# STM32H7A3xxQ register map
File version: 1.0
Registers are 32-bit, read-write, reset 0x0 unless marked. A register's access mark holds for its fields unless they carry their own. Offsets are from the block's base; [hi:lo] are bit positions; {n}, {i} and the like mark numbered series.

## RAMECC
Base 0x52009000
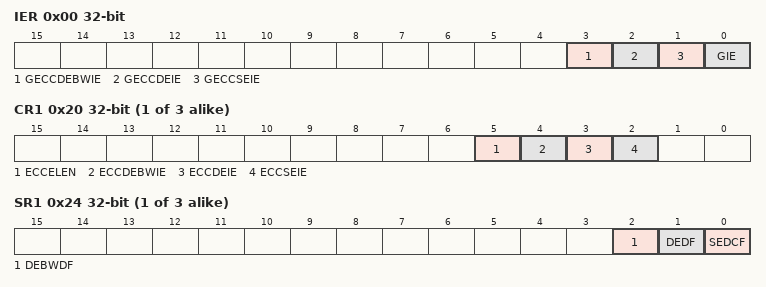
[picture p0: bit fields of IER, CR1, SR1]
0x00 IER — RAMECC interrupt enable register
  [3] GECCDEBWIE — Global ECC double error on byte write (BW) interrupt enable
  [2] GECCDEIE — Global ECC double error interrupt enable
  [1] GECCSEIE — Global ECC single error interrupt enable
  [0] GIE — Global interrupt enable
{0x0+0x20*i} CR{i} (i=1..3) — RAMECC monitor configuration register
  [5] ECCELEN — ECC error latching enable
  [4] ECCDEBWIE — ECC double error on byte write (BW) interrupt enable
  [3] ECCDEIE — ECC double error interrupt enable
  [2] ECCSEIE — ECC single error interrupt enable
{0x4+0x20*i} SR{i} (i=1..3) — RAMECC monitor status register
  [2] DEBWDF — ECC double error on byte write (BW) detected flag
  [1] DEDF — ECC double error detected flag
  [0] SEDCF — ECC single error detected and corrected flag
{0x8+0x20*i} FAR{i} (i=1..3) — RAMECC monitor failing address register
  [31:0] FADD — ECC error failing address
{0xC+0x20*i} FDRL{i} (i=1..3) — RAMECC monitor failing data low register
{0x10+0x20*i} FDRH{i} (i=1..3) — RAMECC monitor failing data high register
{0x14+0x20*i} FECR{i} (i=1..3) — RAMECC monitor failing ECC error code register
  [31:0] FEC — Failing error code

## OCTOSPIM — OCTO Serial Peripheral Interface IO Manager
Base 0x5200B400
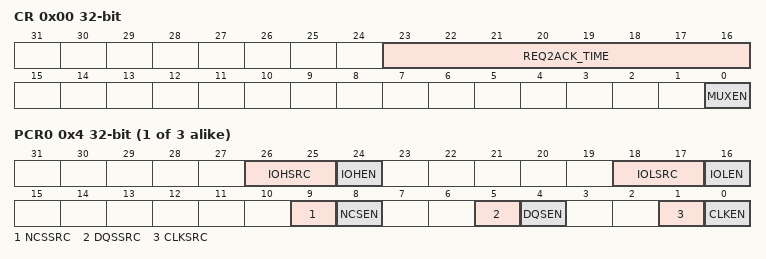
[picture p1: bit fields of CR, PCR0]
0x00 CR — OCTOSPI IO Manager Control register
  [23:16] REQ2ACK_TIME — REQ to ACK time
  [0] MUXEN — Multiplexed mode enable
{0x4+4i} PCR{i} (i=0..2) — OCTOSPI IO Manager Port[1:3] Configuration register
  [26:25] IOHSRC — IO[7:4] Source for Port n
  [24] IOHEN — IO[7:4] Enable for Port n
  [18:17] IOLSRC — IO[3:0] Source for Port n
  [16] IOLEN — IO[3:0] Enable for Port n
  [9] NCSSRC — nCS Source for Port n
  [8] NCSEN — nCS Enable for Port n
  [5] DQSSRC — DQS Source for Port n
  [4] DQSEN — DQS Enable for Port n
  [1] CLKSRC — CLK/CLKn Source for Port n
  [0] CLKEN — CLK/CLKn Enable for Port n

## GFXMMU — GFXMMU registers
Base 0x5200C000
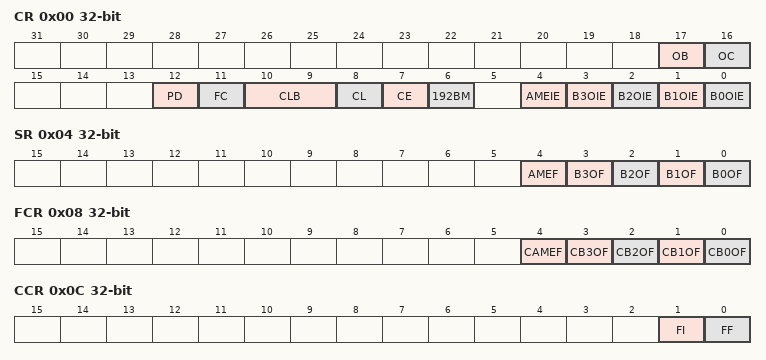
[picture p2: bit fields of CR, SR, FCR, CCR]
0x00 CR — GFXMMU configuration register
  [17] OB — Outer Bufferability
  [16] OC — Outer Cachability
  [12] PD — Prefetch Disable
  [11] FC — Force Caching
  [10:9] CLB — CLB[1:0]: Cache Lock Buffer
  [8] CL — Cache Lock
  [7] CE — Cache Enable
  [6] 192BM — 192 block mode
  [4] AMEIE — AHB master error interrupt enable
  [n] B{n}OIE (n=0..3) — Buffer {n} overflow interrupt enable
0x04 SR — GFXMMU status register
  [4] AMEF — AHB master error flag
  [n] B{n}OF (n=0..3) — Buffer {n} overflow flag
0x08 FCR — GFXMMU flag clear register
  [4] CAMEF — Clear AHB master error flag
  [n] CB{n}OF (n=0..3) — Clear buffer {n} overflow flag
0x0C CCR — GFXMMU Cache Control Register
  [1] FI — Clear buffer 1 overflow flag
  [0] FF — Clear buffer 0 overflow flag
0x10 DVR — GFXMMU default value register
  [31:0] DV — DV[31:0] bits (Default value)
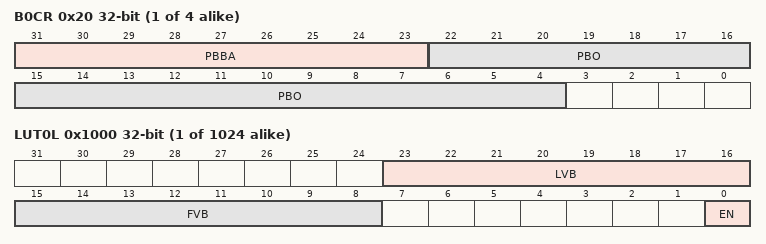
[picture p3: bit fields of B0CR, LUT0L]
{0x20+4i} B{i}CR (i=0..3) — GFXMMU buffer {i} configuration register
  [31:23] PBBA — PBBA[31:23] bits (Physical buffer base address)
  [22:4] PBO — PB0[22:4] bits (Physical buffer offset)
{0x1000+8i} LUT{i}L (i=0..1023) — GFXMMU LUT registers
  [23:16] LVB — LVB[7:0] bits (Last visible block)
  [15:8] FVB — FVB[7:0] bits (First visible block)
  [0] EN — Enable
{0x1004+8i} LUT{i}H (i=0..1023) — GFXMMU LUT registers
  [21:4] LO — LO[21:4] bits (Line offset)

## SYSCFG — System configuration controller
Base 0x58000400
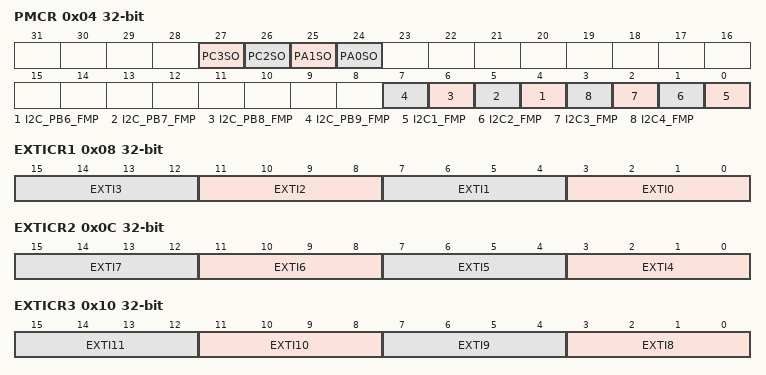
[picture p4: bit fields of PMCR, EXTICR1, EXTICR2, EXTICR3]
0x04 PMCR — SYSCFG peripheral mode configuration register
  [27] PC3SO — PC3 Switch Open
  [26] PC2SO — PC2 Switch Open
  [25] PA1SO — PA1 Switch Open
  [24] PA0SO — PA0 Switch Open
  [n-2] I2C_PB{n}_FMP (n=6..9) — I2C PB{n} Fast mode plus
  [n-1] I2C{n}_FMP (n=1..4) — I2C{n} Fast mode plus
0x08 EXTICR1 — SYSCFG external interrupt configuration registers
  [4n+3:4n] EXTI{n} (n=0..3) — EXTI {n} configuration
0x0C EXTICR2 — SYSCFG external interrupt configuration registers
  [4n-13:4n-16] EXTI{n} (n=4..7) — EXTI {n} configuration
0x10 EXTICR3 — SYSCFG external interrupt configuration registers
  [4n-29:4n-32] EXTI{n} (n=8..11) — EXTI {n} configuration
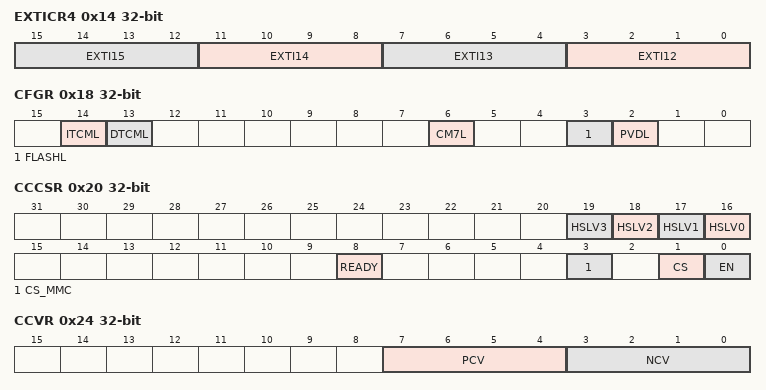
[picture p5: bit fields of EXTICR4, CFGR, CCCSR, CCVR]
0x14 EXTICR4 — SYSCFG external interrupt configuration registers
  [4n-45:4n-48] EXTI{n} (n=12..15) — EXTI {n} configuration
0x18 CFGR — SYSCFG configuration registers
  [14] ITCML — ITCM double ECC error lock bit
  [13] DTCML — DTCM double ECC error lock bit
  [6] CM7L — Cortex-M7 LOCKUP (Hardfault) output enable bit
  [3] FLASHL — FLASH double ECC error lock bit
  [2] PVDL — PVD lock enable bit
0x20 CCCSR — SYSCFG compensation cell control/status register
  [n+16] HSLV{n} (n=0..3) — High-speed at low-voltage
  [8] READY — I/O compensation cell ready flag
  [3] CS_MMC — I/O compensation cell code selection
  [1] CS — I/O compensation cell code selection
  [0] EN — I/O compensation cell enable
0x24 CCVR — SYSCFG compensation cell value register
  [7:4] PCV — PMOS compensation value
  [3:0] NCV — NMOS compensation value
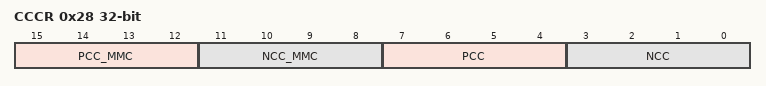
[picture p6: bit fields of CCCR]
0x28 CCCR — SYSCFG compensation cell code register
  [15:12] PCC_MMC — PMOS compensation code
  [11:8] NCC_MMC — NMOS compensation code
  [7:4] PCC — PMOS compensation code
  [3:0] NCC — NMOS compensation code
